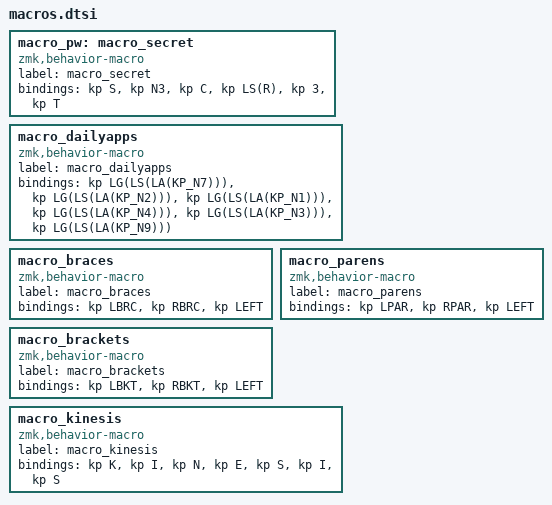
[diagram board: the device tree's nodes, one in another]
  macro_pw: macro_secret {
    compatible = "zmk,behavior-macro";
    label = "macro_secret";
    #binding-cells = <0>;
    bindings = <&kp S>, <&kp N3>, <&kp C>, <&kp LS(R)>, <&kp 3>, <&kp T>;
  };
  macro_dailyapps: macro_dailyapps {
    compatible = "zmk,behavior-macro";
    label = "macro_dailyapps";
    #binding-cells = <0>;
    bindings = <&kp LG(LS(LA(KP_N7)))>, <&kp LG(LS(LA(KP_N2)))>, <&kp LG(LS(LA(KP_N1)))>, <&kp LG(LS(LA(KP_N4)))>, <&kp LG(LS(LA(KP_N3)))>, <&kp LG(LS(LA(KP_N9)))>;
  };
  macro_braces: macro_braces {
    compatible = "zmk,behavior-macro";
    label = "macro_braces";
    #binding-cells = <0>;
    bindings = <&kp LBRC>, <&kp RBRC>, <&kp LEFT>;
  };
  macro_parens: macro_parens {
    compatible = "zmk,behavior-macro";
    label = "macro_parens";
    #binding-cells = <0>;
    bindings = <&kp LPAR>, <&kp RPAR>, <&kp LEFT>;
  };
  macro_brackets: macro_brackets {
    compatible = "zmk,behavior-macro";
    label = "macro_brackets";
    #binding-cells = <0>;
    bindings = <&kp LBKT>, <&kp RBKT>, <&kp LEFT>;
  };
  macro_kinesis: macro_kinesis {
    compatible = "zmk,behavior-macro";
    label = "macro_kinesis";
    #binding-cells = <0>;
    bindings = <&kp K>, <&kp I>, <&kp N>, <&kp E>, <&kp S>, <&kp I>, <&kp S>;
  };
